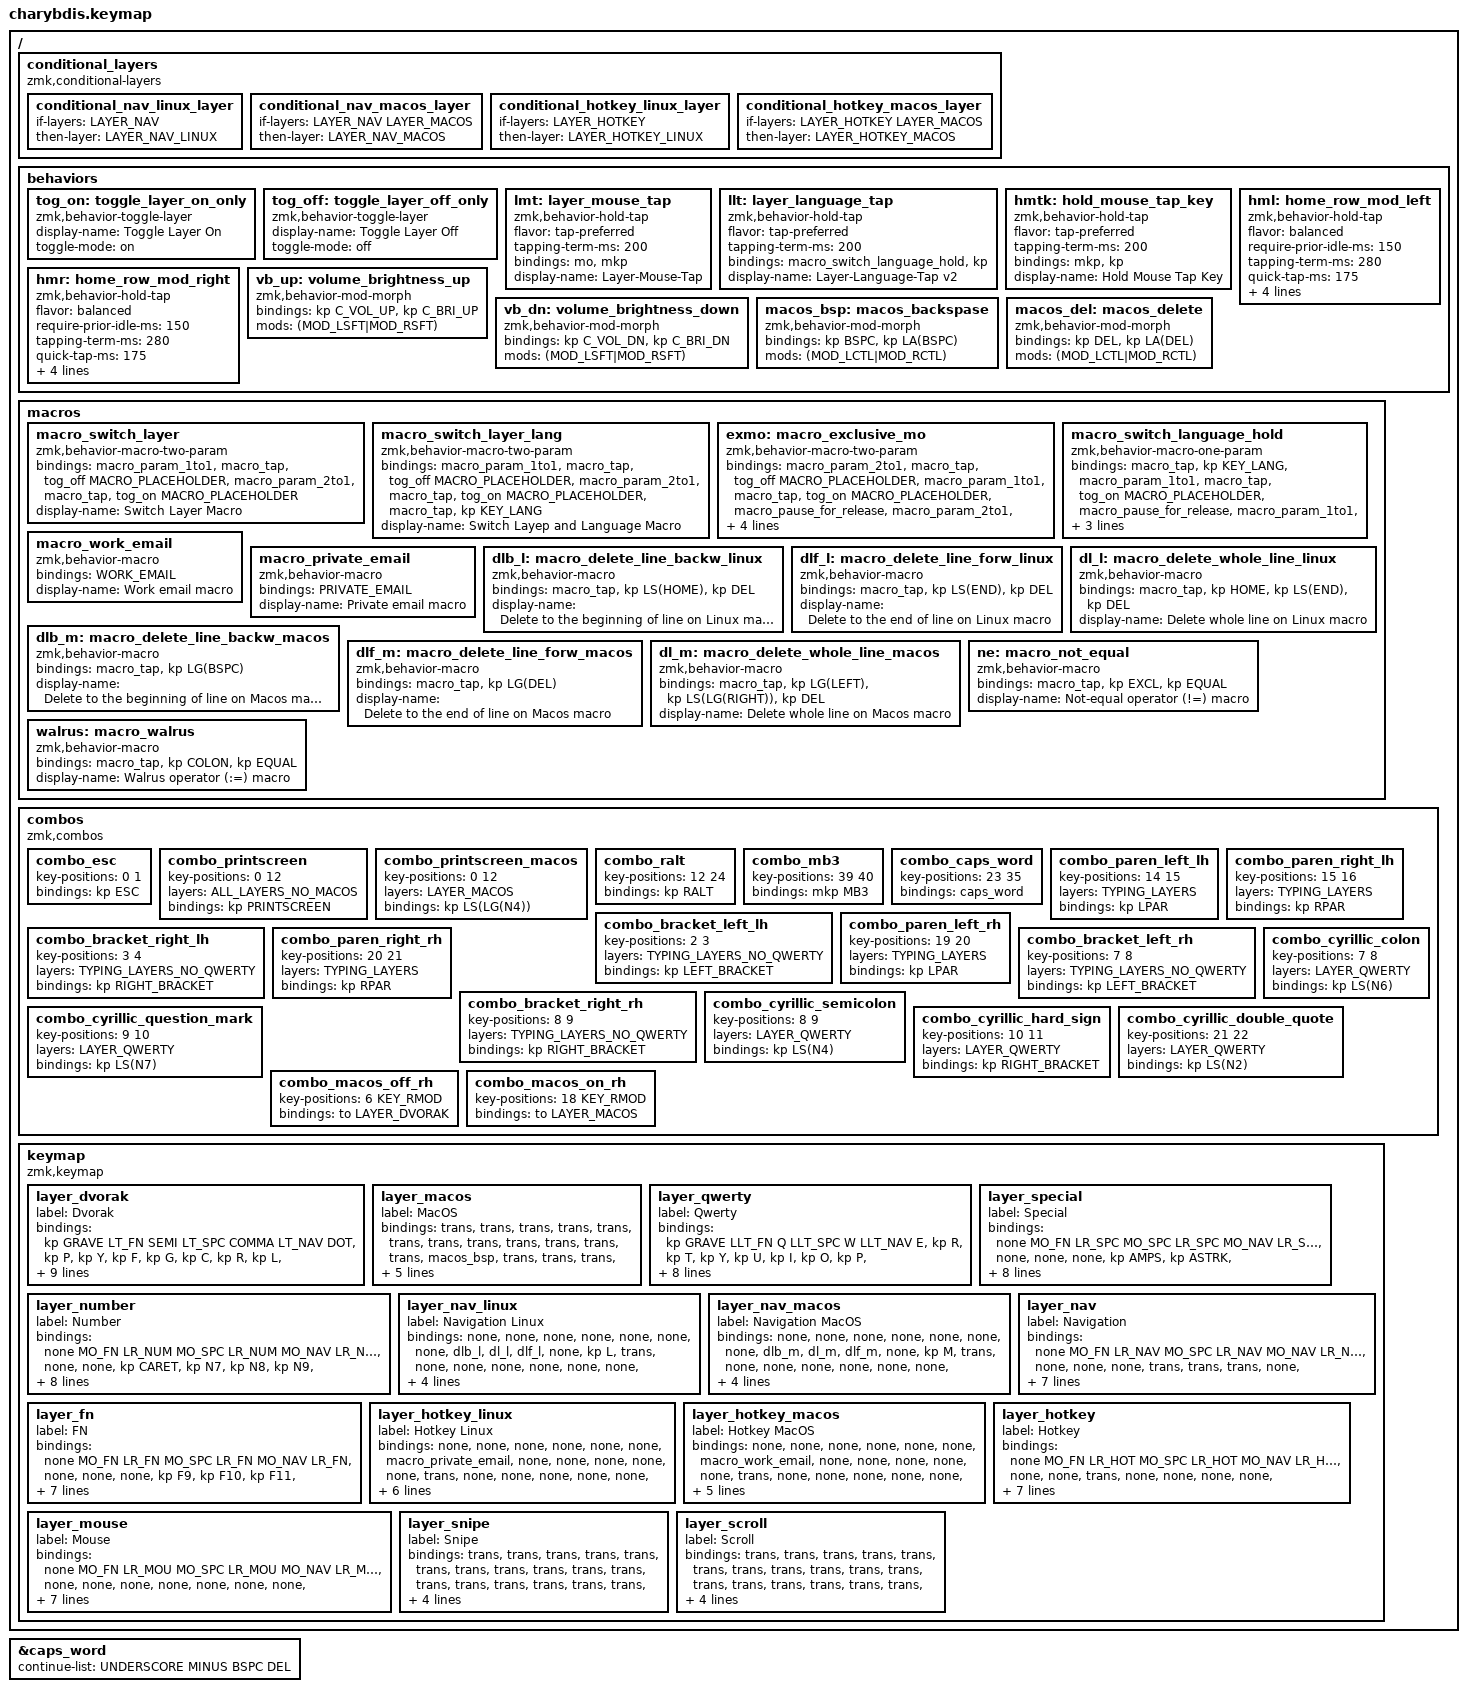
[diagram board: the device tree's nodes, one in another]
#include <behaviors.dtsi>
#include <dt-bindings/zmk/mouse.h>
#include <dt-bindings/zmk/bt.h>
#include <dt-bindings/zmk/keys.h>
#include <dt-bindings/zmk/outputs.h>

#ifndef LAYERS
#define LAYERS

#define LAYER_DVORAK        0
#define LAYER_MACOS         1
#define LAYER_QWERTY        2
#define LAYER_SPEC          3
#define LAYER_NUMBER        4
#define LAYER_NAV_LINUX     5
#define LAYER_NAV_MACOS     6
#define LAYER_NAV           7
#define LAYER_FN            8
#define LAYER_HOTKEY_LINUX  9
#define LAYER_HOTKEY_MACOS  10
#define LAYER_HOTKEY        11
#define LAYER_MOUSE         12
#define LAYER_SNIPE         13
#define LAYER_SCROLL        14

#endif


#define KEY_LAYER_DVORAK_RH 19
#define KEY_LAYER_DVORAK_LH 16
#define KEY_LAYER_QWERTY_RH 7
#define KEY_LAYER_QWERTY_LH 4
#define KEY_LAYER_SPEC_RH 9
#define KEY_LAYER_SPEC_LH 2
#define KEY_LAYER_NUMBER_RH 21
#define KEY_LAYER_NUMBER_LH 14
#define KEY_LAYER_NAV_RH 8
#define KEY_LAYER_NAV_LH 3
#define KEY_LAYER_FN_RH 10
#define KEY_LAYER_FN_LH 1
#define KEY_LAYER_HOTKEY_RH 22
#define KEY_LAYER_HOTKEY_LH 13
#define KEY_LAYER_MOUSE_RH 20
#define KEY_LAYER_MOUSE_LH 15


#define TYPING_LAYERS \
    LAYER_DVORAK \
    LAYER_QWERTY \
    LAYER_MACOS \
    LAYER_SPEC \
    LAYER_NUMBER \
    LAYER_NAV

#define TYPING_LAYERS_NO_QWERTY \
    LAYER_DVORAK \
    LAYER_MACOS \
    LAYER_SPEC \
    LAYER_NUMBER \
    LAYER_NAV

#define ALL_LAYERS_NO_QWERTY \
    LAYER_DVORAK \
    LAYER_MACOS \
    LAYER_SPEC \
    LAYER_NUMBER \
    LAYER_NAV \
    LAYER_FN \
    LAYER_HOTKEY \
    LAYER_MOUSE \
    LAYER_SNIPE \
    LAYER_SCROLL

#define ALL_LAYERS_NO_MACOS \
    LAYER_DVORAK \
    LAYER_QWERTY \
    LAYER_SPEC \
    LAYER_NUMBER \
    LAYER_NAV \
    LAYER_FN \
    LAYER_HOTKEY \
    LAYER_MOUSE \
    LAYER_SNIPE \
    LAYER_SCROLL

#define LR_DVO LAYER_DVORAK
#define LR_QWE LAYER_QWERTY
#define LR_SPC LAYER_SPEC
#define LR_NUM LAYER_NUMBER
#define LR_NAV LAYER_NAV
#define LR_FN  LAYER_FN
#define LR_HOT LAYER_HOTKEY
#define LR_MOU LAYER_MOUSE
#define LR_SNP LAYER_SNIPE
#define LR_SCR LAYER_SCROLL


#define LT_SPC      &lt     LAYER_SPEC
#define LLT_SPC     &llt    LAYER_SPEC
#define MO_SPC      &exmo   LAYER_SPEC
#define LT_NUM      &lt     LAYER_NUMBER
#define LLT_NUM     &llt    LAYER_NUMBER
#define MO_NUM      &exmo   LAYER_NUMBER
#define LT_NAV      &lt     LAYER_NAV
#define LLT_NAV     &llt    LAYER_NAV
#define MO_NAV      &exmo   LAYER_NAV
#define LT_FN       &lt     LAYER_FN
#define LLT_FN      &llt    LAYER_FN
#define MO_FN       &exmo   LAYER_FN
#define LT_MOU      &lt     LAYER_MOUSE
#define LLT_MOU     &llt    LAYER_MOUSE
#define MO_MOU      &exmo   LAYER_MOUSE
#define LT_SCR      &lt     LAYER_SCROLL
#define LLT_SCR     &llt    LAYER_SCROLL
#define MO_SCR      &exmo   LAYER_SCROLL
#define LT_HOT      &lt     LAYER_HOTKEY
#define LLT_HOT     &llt    LAYER_HOTKEY
#define MO_HOT      &exmo   LAYER_HOTKEY


#define COMBO_TO_LAYER_RH(FROM, TO) \
    combo_to_ ## TO ## _from_ ## FROM ## _rh { \
        key-positions = <KEY_ ## TO ## _RH KEY_RMOD>; \
        layers = <FROM>; \
        bindings = <&macro_switch_layer FROM TO>; \
    };

#define COMBO_LAYER_LOOP_RH(LAYER) \
    combo_ ## LAYER ## _loop_rh { \
        key-positions = <KEY_ ## LAYER ## _RH KEY_RMOD>; \
        layers = <LAYER>; \
        bindings = <&none>; \
    };

#define COMBO_LAYER_LOOP_LANG_RH(LAYER) \
    combo_ ## LAYER ## _loop_rh { \
        key-positions = <KEY_ ## LAYER ## _RH KEY_RMOD>; \
        layers = <LAYER>; \
        bindings = <&kp KEY_LANG>; \
    };

#define COMBO_TO_LAYER_MACOS_RH(FROM, TO) \
    combo_to_ ## TO ## _from_ ## FROM ## _rh { \
        key-positions = <KEY_ ## TO ## _RH KEY_RMOD>; \
        layers = <FROM LAYER_MACOS>; \
        bindings = <&macro_switch_layer FROM TO>; \
    };

#define COMBO_LAYER_LOOP_MACOS_RH(LAYER) \
    combo_ ## LAYER ## _loop_macos_rh { \
        key-positions = <KEY_ ## LAYER ## _RH KEY_RMOD>; \
        layers = <LAYER LAYER_MACOS>; \
        bindings = <&none>; \
    };

#define COMBO_LAYER_LOOP_MACOS_LANG_RH(LAYER) \
    combo_ ## LAYER ## _loop_macos_rh { \
        key-positions = <KEY_ ## LAYER ## _RH KEY_RMOD>; \
        layers = <LAYER LAYER_MACOS>; \
        bindings = <&kp KEY_LANG>; \
    };

#define COMBO_TO_LAYER_LANG_RH(FROM, TO) \
    combo_to_ ## TO ## _from_ ## FROM ## _rh { \
        key-positions = <KEY_ ## TO ## _RH KEY_RMOD>; \
        layers = <FROM>; \
        bindings = <&macro_switch_layer_lang FROM TO>; \
    };

#define COMBO_TO_LAYER_LANG_MACOS_RH(FROM, TO) \
    combo_to_ ## TO ## _from_ ## FROM ## _rh { \
        key-positions = <KEY_ ## TO ## _RH KEY_RMOD>; \
        layers = <FROM LAYER_MACOS>; \
        bindings = <&macro_switch_layer_lang FROM TO>; \
    };


#define KEY_LANG LA(SPACE)


#define KEY_LMOD 36
#define KEY_RMOD 40

#define HML_SHF    &hml LSHFT
#define HML_ALT    &hml LALT
#define HML_CMD    &hml LCMD
#define HML_CTR    &hml LCTRL

#define HMR_CTR    &hmr LCTRL
#define HMR_CMD    &hmr LCMD
#define HMR_ALT    &hmr LALT
#define HMR_SHF    &hmr LSHFT

#define HMB1 &hmtk MB1
#define HMB2 &hmtk MB2


#define EM1 &kp K &kp O &kp N
#define EM2 &kp K &kp V
#define EM3 &kp S &kp T &kp A
#define EM4 &kp M &kp A
#define EM5 &kp N &kp T &kp I &kp N &kp DOT &kp M &kp A
#define EM6 &kp T &kp V &kp E
#define EM7 &kp T &kp V &kp E &kp E &kp V
#define EM8 &kp E &kp V
#define EM9 &kp AT &kp C &kp O &kp I
#define EM10 &kp AT &kp G &kp M
#define EM11 &kp N &kp S &kp P &kp A &kp I
#define EM12 &kp A &kp I
#define EM13 &kp D &kp DOT &kp C &kp O &kp M
#define EM14 &kp L &kp DOT &kp C &kp O &kp M

#define WORK_EMAIL \
    <EM1>, \
    <EM3>, \
    <EM5>, \
    <EM7>, \
    <EM9>, \
    <EM11>, \
    <EM13>

#define PRIVATE_EMAIL \
    <EM2>, \
    <EM4>, \
    <EM6>, \
    <EM8>, \
    <EM10>, \
    <EM12>, \
    <EM14>

&caps_word {
    continue-list = <UNDERSCORE MINUS BSPC DEL>;
};

/ {
    conditional_layers {
        compatible = "zmk,conditional-layers";

        conditional_nav_linux_layer {
            if-layers = <LAYER_NAV>;
            then-layer = <LAYER_NAV_LINUX>;
        };

        conditional_nav_macos_layer {
            if-layers = <LAYER_NAV LAYER_MACOS>;
            then-layer = <LAYER_NAV_MACOS>;
        };

        conditional_hotkey_linux_layer {
            if-layers = <LAYER_HOTKEY>;
            then-layer = <LAYER_HOTKEY_LINUX>;
        };

        conditional_hotkey_macos_layer {
            if-layers = <LAYER_HOTKEY LAYER_MACOS>;
            then-layer = <LAYER_HOTKEY_MACOS>;
        };
    };
    
    behaviors {
        tog_on: toggle_layer_on_only {
            compatible = "zmk,behavior-toggle-layer";
            #binding-cells = <1>;
            display-name = "Toggle Layer On";
            toggle-mode = "on";
        };

        tog_off: toggle_layer_off_only {
            compatible = "zmk,behavior-toggle-layer";
            #binding-cells = <1>;
            display-name = "Toggle Layer Off";
            toggle-mode = "off";
        };

        lmt: layer_mouse_tap {
            compatible = "zmk,behavior-hold-tap";
            #binding-cells = <2>;
            flavor = "tap-preferred";
            tapping-term-ms = <200>;
            bindings = <&mo>, <&mkp>;
            display-name = "Layer-Mouse-Tap";
        };

        llt: layer_language_tap {
            compatible = "zmk,behavior-hold-tap";
            #binding-cells = <2>;
            flavor = "tap-preferred";
            tapping-term-ms = <200>;
            bindings = <&macro_switch_language_hold>, <&kp>;
            display-name = "Layer-Language-Tap v2";
        };

        hmtk: hold_mouse_tap_key {
            compatible = "zmk,behavior-hold-tap";
            #binding-cells = <2>;
            flavor = "tap-preferred";
            tapping-term-ms = <200>;
            bindings = <&mkp>, <&kp>;
            display-name = "Hold Mouse Tap Key";
        };

        hml: home_row_mod_left {
            compatible = "zmk,behavior-hold-tap";
            #binding-cells = <2>;
            flavor = "balanced";
            require-prior-idle-ms = <150>;
            tapping-term-ms = <280>;
            quick-tap-ms = <175>;
            bindings = <&kp>, <&kp>;
            hold-trigger-key-positions = <
            0                6  7  8  9  10 11
            12               18 19 20 21 22 23
            24               30 31 32 33 34 35
                  36 37 38   39 40
            >;
            hold-trigger-on-release;
        };

        hmr: home_row_mod_right {
            compatible = "zmk,behavior-hold-tap";
            #binding-cells = <2>;
            flavor = "balanced";
            require-prior-idle-ms = <150>;
            tapping-term-ms = <280>;
            quick-tap-ms = <175>;
            bindings = <&kp>, <&kp>;
            hold-trigger-key-positions = <
                0  1  2  3  4  5 
                12 13 14 15 16 17
                24 25 26 27 28 29
                         36 37 38   39 40
            >;
            hold-trigger-on-release;
        };

        vb_up: volume_brightness_up {
            compatible = "zmk,behavior-mod-morph";
            #binding-cells = <0>;
            bindings = <&kp C_VOL_UP>, <&kp C_BRI_UP>;
            mods = <(MOD_LSFT|MOD_RSFT)>;
        };

        vb_dn: volume_brightness_down {
            compatible = "zmk,behavior-mod-morph";
            #binding-cells = <0>;
            bindings = <&kp C_VOL_DN>, <&kp C_BRI_DN>;
            mods = <(MOD_LSFT|MOD_RSFT)>;
        };

        macos_bsp: macos_backspase {
            compatible = "zmk,behavior-mod-morph";
            #binding-cells = <0>;
            bindings = <&kp BSPC>, <&kp LA(BSPC)>;
            mods = <(MOD_LCTL|MOD_RCTL)>;
        };

        macos_del: macos_delete {
            compatible = "zmk,behavior-mod-morph";
            #binding-cells = <0>;
            bindings = <&kp DEL>, <&kp LA(DEL)>;
            mods = <(MOD_LCTL|MOD_RCTL)>;
        };
    };

    macros {
        // param1: layer_from
        // param2: layer_to
        macro_switch_layer: macro_switch_layer {
            compatible = "zmk,behavior-macro-two-param";
            #binding-cells = <2>;
            bindings 
                = <&macro_param_1to1>
                , <&macro_tap &tog_off MACRO_PLACEHOLDER>
                , <&macro_param_2to1>
                , <&macro_tap &tog_on MACRO_PLACEHOLDER>
                ;
            display-name = "Switch Layer Macro";
        };

        // param1: layer_from
        // param2: layer_to
        macro_switch_layer_lang: macro_switch_layer_lang {
            compatible = "zmk,behavior-macro-two-param";
            #binding-cells = <2>;
            bindings 
                = <&macro_param_1to1>
                , <&macro_tap &tog_off MACRO_PLACEHOLDER>
                , <&macro_param_2to1>
                , <&macro_tap &tog_on MACRO_PLACEHOLDER>
                , <&macro_tap &kp KEY_LANG>
                ;
            display-name = "Switch Layep and Language Macro";
        };
        
        // toggle off layer_from, toggle on layer_to
        // wait for release
        // toggle on layer_from, toggle off layer_to
        // param1: layer_to
        // param2: layer_from
        exmo: macro_exclusive_mo {
            compatible = "zmk,behavior-macro-two-param";
            #binding-cells = <2>;
            bindings 
                = <&macro_param_2to1>
                , <&macro_tap &tog_off MACRO_PLACEHOLDER>
                , <&macro_param_1to1>
                , <&macro_tap &tog_on MACRO_PLACEHOLDER>
                , <&macro_pause_for_release>
                , <&macro_param_2to1>
                , <&macro_tap &tog_on MACRO_PLACEHOLDER>
                , <&macro_param_1to1>
                , <&macro_tap &tog_off MACRO_PLACEHOLDER>
                ;
            display-name = "To Layer Hold Macro";
        };

        macro_switch_language_hold: macro_switch_language_hold {
            compatible = "zmk,behavior-macro-one-param";
            #binding-cells = <1>;
            bindings 
                = <&macro_tap &kp KEY_LANG>
                , <&macro_param_1to1>
                , <&macro_tap &tog_on MACRO_PLACEHOLDER>
                , <&macro_pause_for_release>
                , <&macro_param_1to1>
                , <&macro_tap &tog_off MACRO_PLACEHOLDER>
                , <&macro_tap &kp KEY_LANG>
                ;
            display-name = "Switch Language Hold Macro";
        };

        macro_work_email: macro_work_email {
            compatible = "zmk,behavior-macro";
            #binding-cells = <0>;
            bindings 
                = WORK_EMAIL
                ;
            display-name = "Work email macro";
        };

        macro_private_email: macro_private_email {
            compatible = "zmk,behavior-macro";
            #binding-cells = <0>;
            bindings 
                = PRIVATE_EMAIL
                ;
            display-name = "Private email macro";
        };

        dlb_l: macro_delete_line_backw_linux {
            compatible = "zmk,behavior-macro";
            #binding-cells = <0>;
            bindings 
                = <&macro_tap &kp LS(HOME) &kp DEL>
                ;
            display-name = "Delete to the beginning of line on Linux macro";
        };

        dlf_l: macro_delete_line_forw_linux {
            compatible = "zmk,behavior-macro";
            #binding-cells = <0>;
            bindings 
                = <&macro_tap &kp LS(END) &kp DEL>
                ;
            display-name = "Delete to the end of line on Linux macro";
        };

        dl_l: macro_delete_whole_line_linux {
            compatible = "zmk,behavior-macro";
            #binding-cells = <0>;
            bindings 
                = <&macro_tap &kp HOME &kp LS(END) &kp DEL>
                ;
            display-name = "Delete whole line on Linux macro";
        };

        dlb_m: macro_delete_line_backw_macos {
            compatible = "zmk,behavior-macro";
            #binding-cells = <0>;
            bindings 
                = <&macro_tap &kp LG(BSPC)>
                ;
            display-name = "Delete to the beginning of line on Macos macro";
        };

        dlf_m: macro_delete_line_forw_macos {
            compatible = "zmk,behavior-macro";
            #binding-cells = <0>;
            bindings 
                = <&macro_tap &kp LG(DEL)>
                ;
            display-name = "Delete to the end of line on Macos macro";
        };

        dl_m: macro_delete_whole_line_macos {
            compatible = "zmk,behavior-macro";
            #binding-cells = <0>;
            bindings 
                = <&macro_tap &kp LG(LEFT) &kp LS(LG(RIGHT)) &kp DEL>
                ;
            display-name = "Delete whole line on Macos macro";
        };

        ne: macro_not_equal {
            compatible = "zmk,behavior-macro";
            #binding-cells = <0>;
            bindings 
                = <&macro_tap &kp EXCL &kp EQUAL>
                ;
            display-name = "Not-equal operator (!=) macro";
        };

        walrus: macro_walrus {
            compatible = "zmk,behavior-macro";
            #binding-cells = <0>;
            bindings 
                = <&macro_tap &kp COLON &kp EQUAL>
                ;
            display-name = "Walrus operator (:=) macro";
        };

    };

    /*
        key positions:
        0  1  2  3  4  5     6  7  8  9  10 11
        12 13 14 15 16 17    18 19 20 21 22 23
        24 25 26 27 28 29    30 31 32 33 34 35
                 36 37 38    39 40
    */

    combos {
        compatible = "zmk,combos";

    // ======== Common keys ========
        combo_esc {
            key-positions = <0 1>;
            bindings = <&kp ESC>;
        };
        combo_printscreen {
            key-positions = <0 12>;
            layers = <ALL_LAYERS_NO_MACOS>;
            bindings = <&kp PRINTSCREEN>;
        };
        combo_printscreen_macos {
            key-positions = <0 12>;
            layers = <LAYER_MACOS>;
            bindings = <&kp LS(LG(N4))>;
        };
        combo_ralt {
            key-positions = <12 24>;
            bindings = <&kp RALT>;
        };
        combo_mb3 {
            key-positions = <39 40>;
            bindings = <&mkp MB3>;
        };
        combo_caps_word {
            key-positions = <23 35>;
            bindings = <&caps_word>;
        };
        // left hand
        combo_paren_left_lh {
            key-positions = <14 15>;
            layers = <TYPING_LAYERS>;
            bindings = <&kp LPAR>;
        };
        combo_paren_right_lh {
            key-positions = <15 16>;
            layers = <TYPING_LAYERS>;
            bindings = <&kp RPAR>;
        };
        combo_bracket_left_lh {
            key-positions = <2 3>;
            layers = <TYPING_LAYERS_NO_QWERTY>;
            bindings = <&kp LEFT_BRACKET>;
        };
        combo_bracket_right_lh {
            key-positions = <3 4>;
            layers = <TYPING_LAYERS_NO_QWERTY>;
            bindings = <&kp RIGHT_BRACKET>;
        };
        // right hand
        combo_paren_left_rh {
            key-positions = <19 20>;
            layers = <TYPING_LAYERS>;
            bindings = <&kp LPAR>;
        };
        combo_paren_right_rh {
            key-positions = <20 21>;
            layers = <TYPING_LAYERS>;
            bindings = <&kp RPAR>;
        };
        combo_bracket_left_rh {
            key-positions = <7 8>;
            layers = <TYPING_LAYERS_NO_QWERTY>;
            bindings = <&kp LEFT_BRACKET>;
        };
        combo_bracket_right_rh {
            key-positions = <8 9>;
            layers = <TYPING_LAYERS_NO_QWERTY>;
            bindings = <&kp RIGHT_BRACKET>;
        };
    // ======== Common keys ========

    // ======== Switching between layers ========
        // left hand disabled
        // right hand
        // from LAYER_DVORAK
        COMBO_LAYER_LOOP_MACOS_LANG_RH(LAYER_DVORAK)
        COMBO_TO_LAYER_LANG_MACOS_RH(LAYER_DVORAK, LAYER_QWERTY)
        COMBO_TO_LAYER_MACOS_RH(LAYER_DVORAK, LAYER_SPEC)
        COMBO_TO_LAYER_MACOS_RH(LAYER_DVORAK, LAYER_NUMBER)
        COMBO_TO_LAYER_MACOS_RH(LAYER_DVORAK, LAYER_NAV)
        COMBO_TO_LAYER_MACOS_RH(LAYER_DVORAK, LAYER_FN)
        COMBO_TO_LAYER_MACOS_RH(LAYER_DVORAK, LAYER_HOTKEY)
        COMBO_TO_LAYER_MACOS_RH(LAYER_DVORAK, LAYER_MOUSE)
        // from LAYER_QWERTY
        COMBO_LAYER_LOOP_LANG_RH(LAYER_QWERTY)
        COMBO_TO_LAYER_LANG_RH(LAYER_QWERTY, LAYER_DVORAK)
        COMBO_TO_LAYER_LANG_RH(LAYER_QWERTY, LAYER_SPEC)
        COMBO_TO_LAYER_LANG_RH(LAYER_QWERTY, LAYER_NUMBER)
        COMBO_TO_LAYER_LANG_RH(LAYER_QWERTY, LAYER_NAV)
        COMBO_TO_LAYER_LANG_RH(LAYER_QWERTY, LAYER_FN)
        COMBO_TO_LAYER_LANG_RH(LAYER_QWERTY, LAYER_HOTKEY)
        COMBO_TO_LAYER_LANG_RH(LAYER_QWERTY, LAYER_MOUSE)
        // from LAYER_SPEC
        COMBO_LAYER_LOOP_RH(LAYER_SPEC)
        COMBO_TO_LAYER_RH(LAYER_SPEC, LAYER_DVORAK)
        COMBO_TO_LAYER_LANG_RH(LAYER_SPEC, LAYER_QWERTY)
        COMBO_TO_LAYER_RH(LAYER_SPEC, LAYER_NUMBER)
        COMBO_TO_LAYER_RH(LAYER_SPEC, LAYER_NAV)
        COMBO_TO_LAYER_RH(LAYER_SPEC, LAYER_FN)
        COMBO_TO_LAYER_RH(LAYER_SPEC, LAYER_HOTKEY)
        COMBO_TO_LAYER_RH(LAYER_SPEC, LAYER_MOUSE)
        // from LAYER_NUMBER
        COMBO_LAYER_LOOP_RH(LAYER_NUMBER)
        COMBO_TO_LAYER_RH(LAYER_NUMBER, LAYER_DVORAK)
        COMBO_TO_LAYER_LANG_RH(LAYER_NUMBER, LAYER_QWERTY)
        COMBO_TO_LAYER_RH(LAYER_NUMBER, LAYER_SPEC)
        COMBO_TO_LAYER_RH(LAYER_NUMBER, LAYER_NAV)
        COMBO_TO_LAYER_RH(LAYER_NUMBER, LAYER_FN)
        COMBO_TO_LAYER_RH(LAYER_NUMBER, LAYER_HOTKEY)
        COMBO_TO_LAYER_RH(LAYER_NUMBER, LAYER_MOUSE)
        // from LAYER_NAV
        COMBO_LAYER_LOOP_RH(LAYER_NAV)
        COMBO_TO_LAYER_RH(LAYER_NAV, LAYER_DVORAK)
        COMBO_TO_LAYER_LANG_RH(LAYER_NAV, LAYER_QWERTY)
        COMBO_TO_LAYER_RH(LAYER_NAV, LAYER_SPEC)
        COMBO_TO_LAYER_RH(LAYER_NAV, LAYER_NUMBER)
        COMBO_TO_LAYER_RH(LAYER_NAV, LAYER_FN)
        COMBO_TO_LAYER_RH(LAYER_NAV, LAYER_HOTKEY)
        COMBO_TO_LAYER_RH(LAYER_NAV, LAYER_MOUSE)
        // from LAYER_FN
        COMBO_LAYER_LOOP_RH(LAYER_FN)
        COMBO_TO_LAYER_RH(LAYER_FN, LAYER_DVORAK)
        COMBO_TO_LAYER_LANG_RH(LAYER_FN, LAYER_QWERTY)
        COMBO_TO_LAYER_RH(LAYER_FN, LAYER_SPEC)
        COMBO_TO_LAYER_RH(LAYER_FN, LAYER_NUMBER)
        COMBO_TO_LAYER_RH(LAYER_FN, LAYER_NAV)
        COMBO_TO_LAYER_RH(LAYER_FN, LAYER_HOTKEY)
        COMBO_TO_LAYER_RH(LAYER_FN, LAYER_MOUSE)
        // from LAYER_HOTKEY
        COMBO_LAYER_LOOP_RH(LAYER_HOTKEY)
        COMBO_TO_LAYER_RH(LAYER_HOTKEY, LAYER_DVORAK)
        COMBO_TO_LAYER_LANG_RH(LAYER_HOTKEY, LAYER_QWERTY)
        COMBO_TO_LAYER_RH(LAYER_HOTKEY, LAYER_SPEC)
        COMBO_TO_LAYER_RH(LAYER_HOTKEY, LAYER_NUMBER)
        COMBO_TO_LAYER_RH(LAYER_HOTKEY, LAYER_NAV)
        COMBO_TO_LAYER_RH(LAYER_HOTKEY, LAYER_FN)
        COMBO_TO_LAYER_RH(LAYER_HOTKEY, LAYER_MOUSE)
        // from LAYER_MOUSE
        COMBO_LAYER_LOOP_RH(LAYER_MOUSE)
        COMBO_TO_LAYER_RH(LAYER_MOUSE, LAYER_DVORAK)
        COMBO_TO_LAYER_LANG_RH(LAYER_MOUSE, LAYER_QWERTY)
        COMBO_TO_LAYER_RH(LAYER_MOUSE, LAYER_SPEC)
        COMBO_TO_LAYER_RH(LAYER_MOUSE, LAYER_NUMBER)
        COMBO_TO_LAYER_RH(LAYER_MOUSE, LAYER_NAV)
        COMBO_TO_LAYER_RH(LAYER_MOUSE, LAYER_FN)
        COMBO_TO_LAYER_RH(LAYER_MOUSE, LAYER_HOTKEY)

    // ======== Switching between layers ========

    // ======== Cyrillic missing characters and specials ========
        combo_cyrillic_colon {
            key-positions = <7 8>;
            layers = <LAYER_QWERTY>;
            bindings = <&kp LS(N6)>;
        };
        combo_cyrillic_semicolon {
            key-positions = <8 9>;
            layers = <LAYER_QWERTY>;
            bindings = <&kp LS(N4)>;
        };
        combo_cyrillic_question_mark {
            key-positions = <9 10>;
            layers = <LAYER_QWERTY>;
            bindings = <&kp LS(N7)>;
        };
        combo_cyrillic_hard_sign {
            key-positions = <10 11>;
            layers = <LAYER_QWERTY>;
            bindings = <&kp RIGHT_BRACKET>;
        };
        combo_cyrillic_double_quote {
            key-positions = <21 22>;
            layers = <LAYER_QWERTY>;
            bindings = <&kp LS(N2)>;
        };
    // ======== Cyrillic missing characters and specials ========

    // ======== Toggle MacOS Layer and resetting active layers ========
        // left hand disabled
        // right hand
        combo_macos_off_rh {
            key-positions = <6 KEY_RMOD>;
            bindings = <&to LAYER_DVORAK>;
        };
        combo_macos_on_rh {
            key-positions = <18 KEY_RMOD>;
            bindings = <&to LAYER_MACOS>;
        };
    // ======== Toggle MacOS Layer and resetting active layers ========
        
    };

    keymap {
        compatible = "zmk,keymap";

        layer_dvorak {
            label = "Dvorak";
            bindings = <
                &kp GRAVE    LT_FN SEMI      LT_SPC COMMA    LT_NAV DOT    &kp P        &kp Y            &kp F    &kp G        &kp C        &kp R        &kp L        &kp BACKSLASH
                &kp BSPC     LT_HOT A        LT_NUM O        LT_MOU E      &kp U        &kp I            &kp D    HMB1 H       LT_SCR T     HMB2 N       &kp S        &kp MINUS
                &kp DEL      HML_SHF APOS    HML_ALT Q       HML_CMD J     HML_CTR K    &kp X            &kp B    HMR_CTR M    HMR_CMD W    HMR_ALT V    HMR_SHF Z    &kp SLASH

                                                            &kp SPACE    &kp TAB    &kp ENTER            &mkp MB2    &mkp MB1
            >;
        };
        
        layer_macos {
            label = "MacOS";
            bindings = <
                &trans        &trans    &trans    &trans    &trans    &trans            &trans    &trans    &trans    &trans    &trans    &trans
                &macos_bsp    &trans    &trans    &trans    &trans    &trans            &trans    &trans    &trans    &trans    &trans    &trans
                &macos_del    &trans    &trans    &trans    &trans    &trans            &trans    &trans    &trans    &trans    &trans    &trans
                                                                    
                                                  &trans    &trans    &trans            &trans    &trans
            >;
        };

        layer_qwerty {
            label = "Qwerty";
            bindings = <
                &kp GRAVE    LLT_FN Q     LLT_SPC W     LLT_NAV E    &kp R        &kp T            &kp Y    &kp U        &kp I            &kp O          &kp P            &kp LEFT_BRACKET
                &trans       LLT_HOT A    LLT_NUM S     LLT_MOU D    &kp F        &kp G            &kp H    HMB1 J       LT_SCR K         HMB2 L         &kp SEMICOLON    &kp APOS
                &trans       HML_SHF Z    HML_ALT X     HML_CMD C    HML_CTR V    &kp B            &kp N    HMR_CTR M    HMR_CMD COMMA    HMR_ALT DOT    HMR_SHF SLASH    &kp MINUS

                                                             &trans    &trans    &trans            &trans    &trans
            >;
        };

        layer_special {
            label = "Special";
            bindings = <
                &none     MO_FN LR_SPC      MO_SPC LR_SPC     MO_NAV LR_SPC     &none     &none            &none      &kp AMPS        &kp ASTRK       &kp EQUAL        &kp LS(MINUS)        &kp BACKSLASH
                &trans    MO_HOT LR_SPC     MO_NUM LR_SPC     MO_MOU LR_SPC     &none     &none            &walrus    HMB1 DLLR       LT_SCR PRCNT    HMB2 CARET       &kp LS(EQUAL)        &kp MINUS
                &trans    &trans            &trans            &trans            &trans    &none            &ne        HMR_CTR EXCL    HMR_CMD AT      HMR_ALT HASH     HMR_SHF LS(SLASH)    &kp SLASH

                                                                     &trans    &trans    &trans            &trans    &trans
            >;
        };

        layer_number {
            label = "Number";
            bindings = <
                &none     MO_FN LR_NUM      MO_SPC LR_NUM     MO_NAV LR_NUM     &none     &none            &kp CARET    &kp N7        &kp N8        &kp N9        &kp DOT          &kp COLON
                &trans    MO_HOT LR_NUM     MO_NUM LR_NUM     MO_MOU LR_NUM     &none     &none            &kp EQUAL    HMB1 N4       LT_SCR N5     HMB2 N6       &kp LS(EQUAL)    &kp MINUS
                &trans    &trans            &trans            &trans            &trans    &none            &kp N0       HMR_CTR N1    HMR_CMD N2    HMR_ALT N3    HMR_SHF ASTRK    &kp SLASH

                                                                     &trans    &trans    &trans            &trans      &trans
            >;
        };

        layer_nav_linux {
            label = "Navigation Linux";
            bindings = <
                &none     &none     &none     &none     &none     &none            &none       &dlb_l           &dl_l    &dlf_l            &none      &kp L
                &trans    &none     &none     &none     &none     &none            &none       &kp LC(LEFT)     &none    &kp LC(RIGHT)     &none      &none
                &trans    &trans    &trans    &trans    &trans    &none            &kp HOME    &none            &none    &none             &kp END    &none

                                             &trans    &trans    &trans            &trans        &trans
            >;
        };

        layer_nav_macos {
            label = "Navigation MacOS";
            bindings = <
                &none     &none     &none     &none     &none     &none            &none           &dlb_m           &dl_m    &dlf_m            &none            &kp M
                &trans    &none     &none     &none     &none     &none            &none           &kp LA(LEFT)     &none    &kp LA(RIGHT)     &none            &none
                &trans    &trans    &trans    &trans    &trans    &none            &kp LG(LEFT)    &none            &none    &none             &kp LG(RIGHT)    &none

                                             &trans    &trans    &trans            &trans        &trans
            >;
        };

        layer_nav {
            label = "Navigation";
            bindings = <
                &none     MO_FN LR_NAV      MO_SPC LR_NAV     MO_NAV LR_NAV     &none     &none            &none        &trans      &trans       &trans       &none        &trans
                &trans    MO_HOT LR_NAV     MO_NUM LR_NAV     MO_MOU LR_NAV     &none     &none            &kp PG_UP    &trans      &kp UP      &trans       &kp PG_DN    &none
                &trans    &trans            &trans            &trans            &trans    &none            &trans       &kp LEFT    &kp DOWN    &kp RIGHT    &trans       &none

                                                                     &trans    &trans    &trans            &trans        &trans
            >;
        };

        layer_fn {
            label = "FN";
            bindings = <
                &none     MO_FN LR_FN      MO_SPC LR_FN     MO_NAV LR_FN     &none     &none            &none    &kp F9        &kp F10       &kp F11       &kp F12       &bootloader
                &trans    MO_HOT LR_FN     MO_NUM LR_FN     MO_MOU LR_FN     &none     &none            &none    HMB1 F5       LT_SCR F6     HMB2 F7       &kp F8        &sys_reset
                &trans    &trans           &trans           &trans           &trans    &none            &none    HMR_CTR F1    HMR_CMD F2    HMR_ALT F3    HMR_SHF F4    &none

                                                                  &trans    &trans    &trans            &trans    &trans
            >;
        };
        
        layer_hotkey_linux {
            label = "Hotkey Linux";
            bindings = <
                &none     &none     &none     &none     &none     &none            &macro_private_email    &none            &none                &none        &none        &none
                &trans    &none     &none     &none     &none     &none            &none                   &kp LC(X)        LT_SCR LC(C)         &kp LC(V)    &kp LC(S)    &none
                &trans    &trans    &trans    &trans    &trans    &none            &none                   HMR_CTR LC(Z)    HMR_CMD LC(LS(Z))    &trans       &trans       &none
                                                                    
                                             &trans    &trans    &trans            &trans    &trans
            >;
        };
        
        layer_hotkey_macos {
            label = "Hotkey MacOS";
            bindings = <
                &none     &none     &none     &none     &none     &none            &macro_work_email    &none            &none                &none                  &none               &none
                &trans    &none     &none     &none     &none     &none            &none                &kp LG(X)        LT_SCR LG(C)         &kp LG(V)              &kp LG(S)           &none
                &trans    &trans    &trans    &trans    &trans    &none            &none                HMR_CTR LG(Z)    HMR_CMD LG(LS(Z))    HMR_ALT LC(LEFT)       HMR_SHF LC(RIGHT)   &none
                                                                    
                                             &trans    &trans    &trans            &trans    &trans
            >;
        };
        
        layer_hotkey {
            label = "Hotkey";
            bindings = <
                &none     MO_FN LR_HOT      MO_SPC LR_HOT     MO_NAV LR_HOT     &none     &none            &trans    &none     &none     &none     &none     &kp C_MUTE
                &trans    MO_HOT LR_HOT     MO_NUM LR_HOT     MO_MOU LR_HOT     &none     &none            &none     &trans    &trans    &trans    &trans    &vb_up
                &trans    &trans            &trans            &trans            &trans    &none            &none     &trans    &trans    &trans    &trans    &vb_dn

                                                                     &trans    &trans    &trans            &trans    &trans
            >;
        };

        layer_mouse {
            label = "Mouse";
            bindings = <
                &none     MO_FN LR_MOU      MO_SPC LR_MOU     MO_NAV LR_MOU     &none     &none            &none    &none        &none               &none        &none              &none
                &trans    MO_HOT LR_MOU     MO_NUM LR_MOU     MO_MOU LR_MOU     &none     &none            &none    &mkp MB1     &lmt LR_SCR MB3     &mkp MB2     &none              &none
                &trans    &trans            &trans            &trans            &trans    &none            &none    &mkp MB4     &none               &mkp MB5     &mo LAYER_SNIPE    &none

                                                                     &trans    &trans    &trans            &trans    &trans
            >;
        };
        
        layer_snipe {
            label = "Snipe";
            bindings = <
                &trans    &trans    &trans    &trans    &trans    &trans            &trans    &trans    &trans    &trans    &trans    &trans
                &trans    &trans    &trans    &trans    &trans    &trans            &trans    &trans    &trans    &trans    &trans    &trans
                &trans    &trans    &trans    &trans    &trans    &trans            &trans    &trans    &trans    &trans    &trans    &trans
                                                                    
                                              &trans    &trans    &trans            &trans    &trans
            >;
        };
        
        layer_scroll {
            label = "Scroll";
            bindings = <
                &trans    &trans    &trans    &trans    &trans    &trans            &trans    &trans    &trans    &trans    &trans    &trans
                &trans    &trans    &trans    &trans    &trans    &trans            &trans    &trans    &trans    &trans    &trans    &trans
                &trans    &trans    &trans    &trans    &trans    &trans            &trans    &trans    &trans    &trans    &trans    &trans
                                                                    
                                              &trans    &trans    &trans            &trans    &trans
            >;
        };

        /*
        // empty_layer {
        //     label = "Empty";
        //     bindings = <
        //         &trans    &trans    &trans    &trans    &trans    &trans            &trans    &trans    &trans    &trans    &trans    &trans
        //         &trans    &trans    &trans    &trans    &trans    &trans            &trans    &trans    &trans    &trans    &trans    &trans
        //         &trans    &trans    &trans    &trans    &trans    &trans            &trans    &trans    &trans    &trans    &trans    &trans
        //                                                                                                                                     
        //                                       &trans    &trans    &trans            &trans    &trans
        //     >;
        // };
        */

    };
};
